# MKW30Z4 register map
Vendor: Freescale Semiconductor, Inc.; Series: Kinetis_W; File version: 1.6
CPU: CM0PLUS r0p0, little endian, no MPU, no FPU, VTOR, 2 interrupt priority bits
Registers are 32-bit, read-write, reset 0x0 unless marked. A register's access mark holds for its fields unless they carry their own. Offsets are from the block's base; [hi:lo] are bit positions; {n}, {i} and the like mark numbered series; 'fields as' and 'values as' point back to an identical list.

## LTC0 — LTC
Base 0x40058000
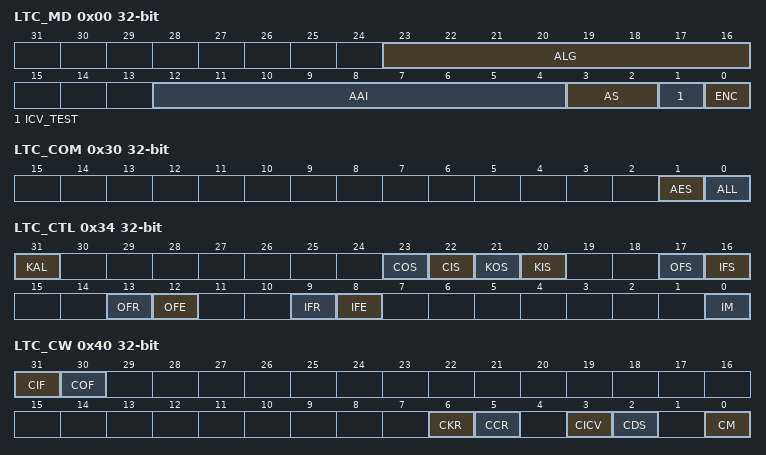
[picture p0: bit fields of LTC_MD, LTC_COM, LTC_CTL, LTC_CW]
0x00 LTC_MD — LTC Mode Register (non-PKHA/non-RNG use)
  [23:16] ALG — Algorithm. This field specifies which algorithm is being selected.
    16=AES
  [12:4] AAI — Additional Algorithm information
  [3:2] AS — Algorithm State
    0=Update; 1=Initialize; 2=Finalize; 3=Initialize/Finalize
  [1] ICV_TEST — ICV Checking / Test AES fault detection
  [0] ENC — Encrypt/Decrypt. This bit selects encryption or decryption.
    0=Decrypt; 1=Encrypt
0x08 LTC_KS reset 0x10 — LTC Key Size Register
  [31:0] KS — Key Size. This is the size of a Key measured in bytes
0x10 LTC_DS — LTC Data Size Register
  [11:0] DS — Data Size
0x18 LTC_ICVS — LTC ICV Size Register
  [4:0] ICVS — ICV Size, in Bytes.
0x30 LTC_COM — LTC Command Register
  [1] AES wo — Reset AESA. Writing a 1 to this bit resets the AES Accelerator core engine.
    0=Do Not Reset; 1=Reset AES Accelerator
  [0] ALL wo — Reset All Internal Logic
    0=Do Not Reset; 1=Reset all CHAs in use by this CCB
0x34 LTC_CTL — LTC Control Register
  [31] KAL — Key Register Access Lock
    0=Key Register is readable; 1=Key Register is not readable
  [23] COS — Context Register Output Byte Swap
    0=Do Not Byte Swap Data; 1=Byte Swap Data
  [22] CIS — Context Register Input Byte Swap
    0=Do Not Byte Swap Data; 1=Byte Swap Data
  [21] KOS — Key Register Output Byte Swap
    0=Do Not Byte Swap Data; 1=Byte Swap Data
  [20] KIS — Key Register Input Byte Swap
    0=Do Not Byte Swap Data; 1=Byte Swap Data
  [17] OFS — Output FIFO Byte Swap. Byte swap all data that is read from the Onput FIFO.
    0=Do Not Byte Swap Data; 1=Byte Swap Data
  [16] IFS — Input FIFO Byte Swap. Byte swap all data that is written to the Input FIFO.
    0=Do Not Byte Swap Data; 1=Byte Swap Data
  [13] OFR — Output FIFO DMA Request Size
    0=DMA request size is 1 entry; 1=DMA request size is 4 entries
  [12] OFE — Output FIFO DMA Enable.
    0=DMA Request and Done signals disabled for the Output FIFO; 1=DMA Request and Done signals enabled for the Output FIFO
  [9] IFR — Input FIFO DMA Request Size
    values as OFR
  [8] IFE — Input FIFO DMA Enable.
    0=DMA Request and Done signals disabled for the Input FIFO; 1=DMA Request and Done signals enabled for the Input FIFO
  [0] IM — Interrupt Mask. Once this bit is set, it can only be cleared by hard reset.
    0=Interrupt not masked; 1=Interrupt masked
0x40 LTC_CW — LTC Clear Written Register
  [31] CIF wo — Clear Input FIFO. Writing a 1 to this bit causes the Input Data FIFO.
  [30] COF wo — Clear Output FIFO. Writing a 1 to this bit causes the Output FIFO to be cleared.
  [6] CKR wo — Clear the Key Register
  [5] CCR wo — Clear the Context Register. Writing a one to this bit causes the Context Register to be cleared.
  [3] CICV wo — Clear the ICV Size Register. Writing a one to this bit causes the ICV Size Register to be cleared.
  [2] CDS wo — Clear the Data Size Register
  [0] CM wo — Clear the Mode Register. Writing a one to this bit causes the Mode Register to be cleared.
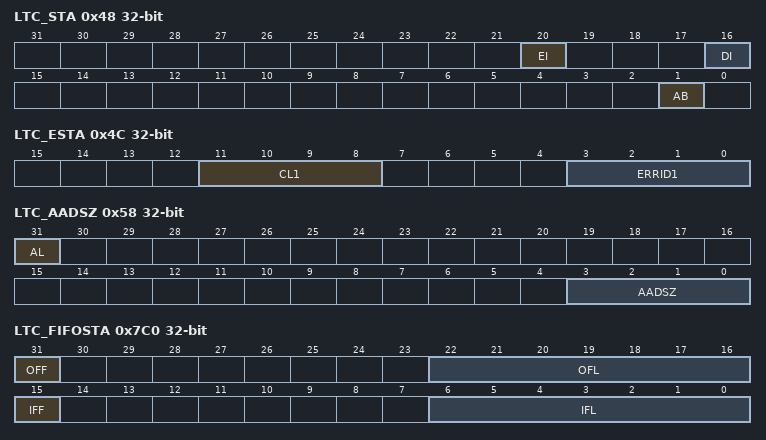
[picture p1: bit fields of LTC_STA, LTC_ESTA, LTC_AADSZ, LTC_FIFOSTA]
0x48 LTC_STA — LTC Status Register
  [20] EI ro — Error Interrupt
    0=Not Error; 1=Error Interrupt
  [16] DI — Done Interrupt
  [1] AB ro — AESA Busy
    0=AESA Idle; 1=AESA Busy
0x4C LTC_ESTA ro — LTC Error Status Register
  [11:8] CL1 — algorithms. The algorithms field indicates which algorithm is asserting an error. Others reserved
    0=LTC General Error; 1=AES
  [3:0] ERRID1 — Error ID 1
    1=Mode Error; 2=Data Size Error; 3=Key Size Error; 6=Data Arrived out of Sequence Error; 10=ICV Check Failed; 11=Internal Hardware Failure; 12=CCM AAD Size Error (either 1. AAD flag in B0 =1 and no AAD type provided, 2. AAD flag in B0 = 0 and AAD povided, or 3. AAD flag in B0 =1 and not enough AAD provided - expecting more based on AAD size.); 15=Invalid Crypto Engine Selected
0x58 LTC_AADSZ — LTC AAD Size Register
  [31] AL — AAD Last. Only AAD data will be written into the Input FIFO.
  [3:0] AADSZ — AAD size in Bytes, mod 16.
{0x100+4i} LTC_CTX_{i} (i=0..15) — LTC Context Register
  [31:0] CTX
{0x200+4i} LTC_KEY_{i} (i=0..3) — LTC Key Registers
  [31:0] KEY
0x7C0 LTC_FIFOSTA ro — LTC FIFO Status Register
  [31] OFF — Output FIFO Full. The Output FIFO is full and should not be written to.
  [22:16] OFL — Output FIFO Level. These bits indicate the current number of entries in the Output FIFO.
  [15] IFF — Input FIFO Full. The Input FIFO is full and should not be written to.
  [6:0] IFL — Input FIFO Level. These bits indicate the current number of entries in the Input FIFO.
0x7E0 LTC_IFIFO wo — LTC Input Data FIFO
0x7F0 LTC_OFIFO ro — LTC Output Data FIFO
  [31:0] OFIFO — Output FIFO
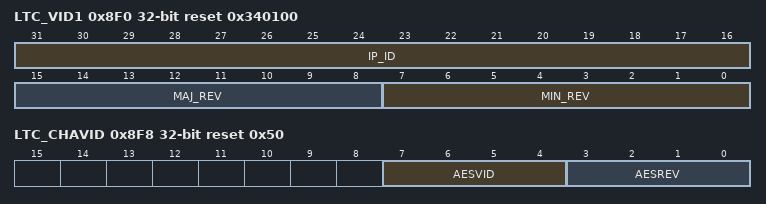
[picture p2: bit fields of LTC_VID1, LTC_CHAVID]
0x8F0 LTC_VID1 ro reset 0x340100 — LTC Version ID Register
  [31:16] IP_ID
  [15:8] MAJ_REV — Major revision number(0x01).
  [7:0] MIN_REV — Minor revision number(0x00).
0x8F8 LTC_CHAVID ro reset 0x50 — LTC CHA Version ID Register
  [7:4] AESVID — AES Version ID(0x5).
  [3:0] AESREV — AES Revision Number(0x0).

## Notices in the file
Redistribution and use in source and binary forms, with or without modification,
are permitted provided that the following conditions are met:
o Redistributions of source code must retain the above copyright notice, this list
of conditions and the following disclaimer.
o Redistributions in binary form must reproduce the above copyright notice, this
list of conditions and the following disclaimer in the documentation and/or
other materials provided with the distribution.
o Neither the name of Freescale Semiconductor, Inc. nor the names of its
contributors may be used to endorse or promote products derived from this
software without specific prior written permission.
THIS SOFTWARE IS PROVIDED BY THE COPYRIGHT HOLDERS AND CONTRIBUTORS "AS IS" AND
ANY EXPRESS OR IMPLIED WARRANTIES, INCLUDING, BUT NOT LIMITED TO, THE IMPLIED
WARRANTIES OF MERCHANTABILITY AND FITNESS FOR A PARTICULAR PURPOSE ARE
DISCLAIMED. IN NO EVENT SHALL THE COPYRIGHT HOLDER OR CONTRIBUTORS BE LIABLE FOR
ANY DIRECT, INDIRECT, INCIDENTAL, SPECIAL, EXEMPLARY, OR CONSEQUENTIAL DAMAGES
(INCLUDING, BUT NOT LIMITED TO, PROCUREMENT OF SUBSTITUTE GOODS OR SERVICES;
LOSS OF USE, DATA, OR PROFITS; OR BUSINESS INTERRUPTION) HOWEVER CAUSED AND ON
ANY THEORY OF LIABILITY, WHETHER IN CONTRACT, STRICT LIABILITY, OR TORT
(INCLUDING NEGLIGENCE OR OTHERWISE) ARISING IN ANY WAY OUT OF THE USE OF THIS
SOFTWARE, EVEN IF ADVISED OF THE POSSIBILITY OF SUCH DAMAGE.
